AUTOSAR XML (schema 4-2-2)
package /STELLANTIS/EPT/ASWCs
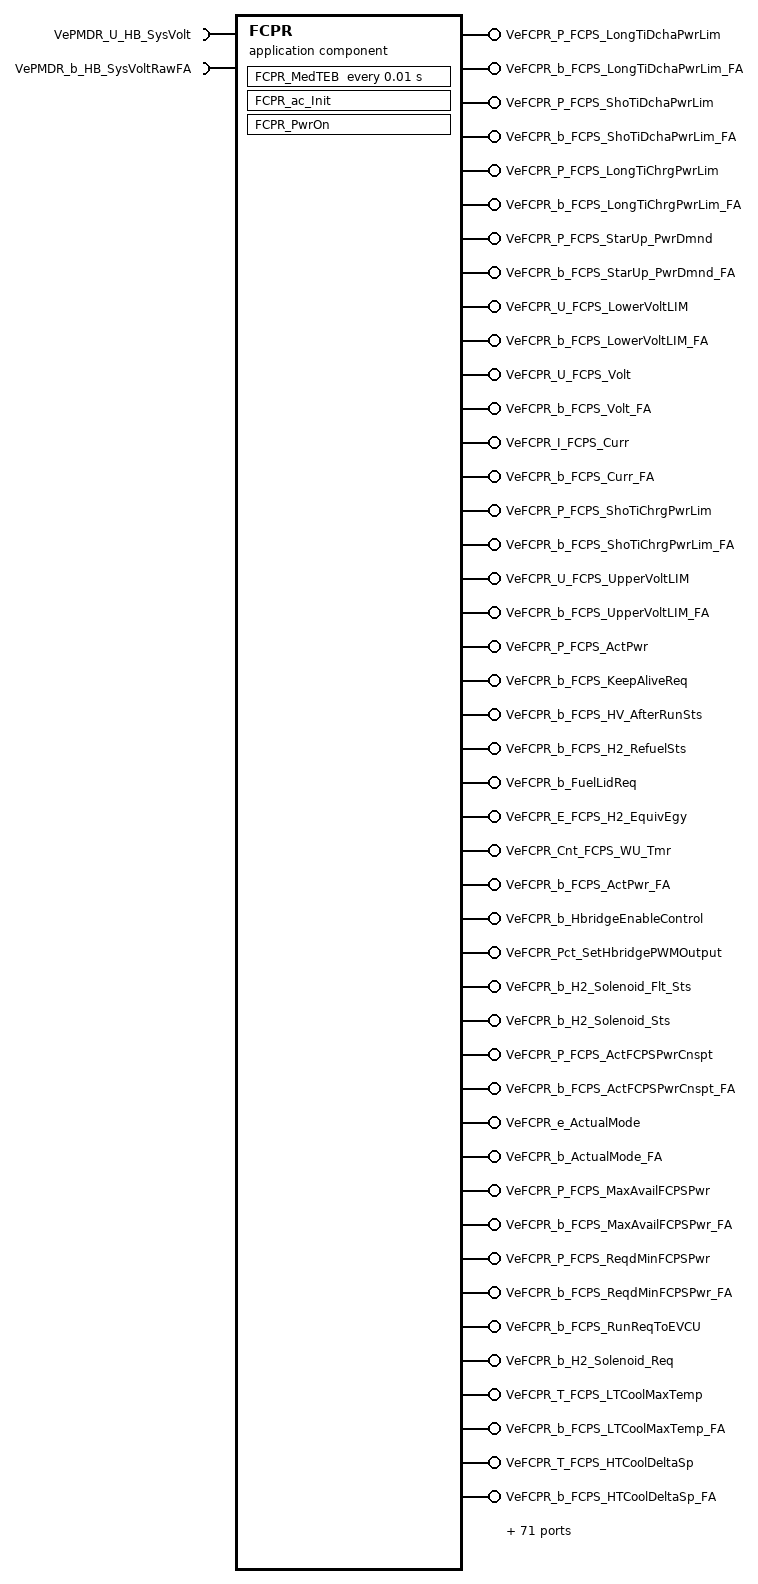
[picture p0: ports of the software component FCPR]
  application sw component type FCPR
    require port VePMDR_U_HB_SysVolt: nonqueued-receiver-com-spec{data-element=Value, init-value=0}, required-interface=VePMDR_U_HB_SysVolt
    require port VePMDR_b_HB_SysVoltRawFA: nonqueued-receiver-com-spec{data-element=Value, init-value=0}, required-interface=VePMDR_b_HB_SysVoltRawFA
    115 x provide port:
      VeFCPR_P_FCPS_LongTiDchaPwrLim: nonqueued-sender-com-spec{data-element=Value, init-value=0}, provided-interface=VeFCPR_P_FCPS_LongTiDchaPwrLim
      VeFCPR_b_FCPS_LongTiDchaPwrLim_FA: nonqueued-sender-com-spec{data-element=Value, init-value=0}, provided-interface=VeFCPR_b_FCPS_LongTiDchaPwrLim_FA
      VeFCPR_P_FCPS_ShoTiDchaPwrLim: nonqueued-sender-com-spec{data-element=Value, init-value=0}, provided-interface=VeFCPR_P_FCPS_ShoTiDchaPwrLim
      VeFCPR_b_FCPS_ShoTiDchaPwrLim_FA: nonqueued-sender-com-spec{data-element=Value, init-value=0}, provided-interface=VeFCPR_b_FCPS_ShoTiDchaPwrLim_FA
      VeFCPR_P_FCPS_LongTiChrgPwrLim: nonqueued-sender-com-spec{data-element=Value, init-value=0}, provided-interface=VeFCPR_P_FCPS_LongTiChrgPwrLim
      VeFCPR_b_FCPS_LongTiChrgPwrLim_FA: nonqueued-sender-com-spec{data-element=Value, init-value=0}, provided-interface=VeFCPR_b_FCPS_LongTiChrgPwrLim_FA
      VeFCPR_P_FCPS_StarUp_PwrDmnd: nonqueued-sender-com-spec{data-element=Value, init-value=0}, provided-interface=VeFCPR_P_FCPS_StarUp_PwrDmnd
      VeFCPR_b_FCPS_StarUp_PwrDmnd_FA: nonqueued-sender-com-spec{data-element=Value, init-value=0}, provided-interface=VeFCPR_b_FCPS_StarUp_PwrDmnd_FA
      VeFCPR_U_FCPS_LowerVoltLIM: nonqueued-sender-com-spec{data-element=Value, init-value=0}, provided-interface=VeFCPR_U_FCPS_LowerVoltLIM
      VeFCPR_b_FCPS_LowerVoltLIM_FA: nonqueued-sender-com-spec{data-element=Value, init-value=0}, provided-interface=VeFCPR_b_FCPS_LowerVoltLIM_FA
      VeFCPR_U_FCPS_Volt: nonqueued-sender-com-spec{data-element=Value, init-value=0}, provided-interface=VeFCPR_U_FCPS_Volt
      VeFCPR_b_FCPS_Volt_FA: nonqueued-sender-com-spec{data-element=Value, init-value=0}, provided-interface=VeFCPR_b_FCPS_Volt_FA
      VeFCPR_I_FCPS_Curr: nonqueued-sender-com-spec{data-element=Value, init-value=0}, provided-interface=VeFCPR_I_FCPS_Curr
      VeFCPR_b_FCPS_Curr_FA: nonqueued-sender-com-spec{data-element=Value, init-value=0}, provided-interface=VeFCPR_b_FCPS_Curr_FA
      VeFCPR_P_FCPS_ShoTiChrgPwrLim: nonqueued-sender-com-spec{data-element=Value, init-value=0}, provided-interface=VeFCPR_P_FCPS_ShoTiChrgPwrLim
      VeFCPR_b_FCPS_ShoTiChrgPwrLim_FA: nonqueued-sender-com-spec{data-element=Value, init-value=0}, provided-interface=VeFCPR_b_FCPS_ShoTiChrgPwrLim_FA
      VeFCPR_U_FCPS_UpperVoltLIM: nonqueued-sender-com-spec{data-element=Value, init-value=0}, provided-interface=VeFCPR_U_FCPS_UpperVoltLIM
      VeFCPR_b_FCPS_UpperVoltLIM_FA: nonqueued-sender-com-spec{data-element=Value, init-value=0}, provided-interface=VeFCPR_b_FCPS_UpperVoltLIM_FA
      VeFCPR_P_FCPS_ActPwr: nonqueued-sender-com-spec{data-element=Value, init-value=0}, provided-interface=VeFCPR_P_FCPS_ActPwr
      VeFCPR_b_FCPS_KeepAliveReq: nonqueued-sender-com-spec{data-element=Value, init-value=0}, provided-interface=VeFCPR_b_FCPS_KeepAliveReq
      VeFCPR_b_FCPS_HV_AfterRunSts: nonqueued-sender-com-spec{data-element=Value, init-value=0}, provided-interface=VeFCPR_b_FCPS_HV_AfterRunSts
      VeFCPR_b_FCPS_H2_RefuelSts: nonqueued-sender-com-spec{data-element=Value, init-value=0}, provided-interface=VeFCPR_b_FCPS_H2_RefuelSts
      VeFCPR_b_FuelLidReq: nonqueued-sender-com-spec{data-element=Value, init-value=0}, provided-interface=VeFCPR_b_FuelLidReq
      VeFCPR_E_FCPS_H2_EquivEgy: nonqueued-sender-com-spec{data-element=Value, init-value=0}, provided-interface=VeFCPR_E_FCPS_H2_EquivEgy
      VeFCPR_Cnt_FCPS_WU_Tmr: nonqueued-sender-com-spec{data-element=Value, init-value=0}, provided-interface=VeFCPR_Cnt_FCPS_WU_Tmr
      VeFCPR_b_FCPS_ActPwr_FA: nonqueued-sender-com-spec{data-element=Value, init-value=0}, provided-interface=VeFCPR_b_FCPS_ActPwr_FA
      VeFCPR_b_HbridgeEnableControl: nonqueued-sender-com-spec{data-element=Value, init-value=0}, provided-interface=VeFCPR_b_HbridgeEnableControl
      VeFCPR_Pct_SetHbridgePWMOutput: nonqueued-sender-com-spec{data-element=Value, init-value=0}, provided-interface=VeFCPR_Pct_SetHbridgePWMOutput
      VeFCPR_b_H2_Solenoid_Flt_Sts: nonqueued-sender-com-spec{data-element=Value, init-value=0}, provided-interface=VeFCPR_b_H2_Solenoid_Flt_Sts
      VeFCPR_b_H2_Solenoid_Sts: nonqueued-sender-com-spec{data-element=Value, init-value=0}, provided-interface=VeFCPR_b_H2_Solenoid_Sts
      VeFCPR_P_FCPS_ActFCPSPwrCnspt: nonqueued-sender-com-spec{data-element=Value, init-value=0}, provided-interface=VeFCPR_P_FCPS_ActFCPSPwrCnspt
      VeFCPR_b_FCPS_ActFCPSPwrCnspt_FA: nonqueued-sender-com-spec{data-element=Value, init-value=0}, provided-interface=VeFCPR_b_FCPS_ActFCPSPwrCnspt_FA
      VeFCPR_e_ActualMode: nonqueued-sender-com-spec{data-element=Value, init-value=CeFCPR_e_ActualMode_NotAvailable}, provided-interface=VeFCPR_e_ActualMode
      VeFCPR_b_ActualMode_FA: nonqueued-sender-com-spec{data-element=Value, init-value=0}, provided-interface=VeFCPR_b_ActualMode_FA
      VeFCPR_P_FCPS_MaxAvailFCPSPwr: nonqueued-sender-com-spec{data-element=Value, init-value=0}, provided-interface=VeFCPR_P_FCPS_MaxAvailFCPSPwr
      VeFCPR_b_FCPS_MaxAvailFCPSPwr_FA: nonqueued-sender-com-spec{data-element=Value, init-value=0}, provided-interface=VeFCPR_b_FCPS_MaxAvailFCPSPwr_FA
      VeFCPR_P_FCPS_ReqdMinFCPSPwr: nonqueued-sender-com-spec{data-element=Value, init-value=0}, provided-interface=VeFCPR_P_FCPS_ReqdMinFCPSPwr
      VeFCPR_b_FCPS_ReqdMinFCPSPwr_FA: nonqueued-sender-com-spec{data-element=Value, init-value=0}, provided-interface=VeFCPR_b_FCPS_ReqdMinFCPSPwr_FA
      VeFCPR_b_FCPS_RunReqToEVCU: nonqueued-sender-com-spec{data-element=Value, init-value=0}, provided-interface=VeFCPR_b_FCPS_RunReqToEVCU
      VeFCPR_b_H2_Solenoid_Req: nonqueued-sender-com-spec{data-element=Value, init-value=0}, provided-interface=VeFCPR_b_H2_Solenoid_Req
      VeFCPR_T_FCPS_LTCoolMaxTemp: nonqueued-sender-com-spec{data-element=Value, init-value=0}, provided-interface=VeFCPR_T_FCPS_LTCoolMaxTemp
      VeFCPR_b_FCPS_LTCoolMaxTemp_FA: nonqueued-sender-com-spec{data-element=Value, init-value=0}, provided-interface=VeFCPR_b_FCPS_LTCoolMaxTemp_FA
      VeFCPR_T_FCPS_HTCoolDeltaSp: nonqueued-sender-com-spec{data-element=Value, init-value=0}, provided-interface=VeFCPR_T_FCPS_HTCoolDeltaSp
      VeFCPR_b_FCPS_HTCoolDeltaSp_FA: nonqueued-sender-com-spec{data-element=Value, init-value=0}, provided-interface=VeFCPR_b_FCPS_HTCoolDeltaSp_FA
      VeFCPR_T_FCPS_HTCoolOutTemp: nonqueued-sender-com-spec{data-element=Value, init-value=0}, provided-interface=VeFCPR_T_FCPS_HTCoolOutTemp
      VeFCPR_b_FCPS_HTCoolOutTemp_FA: nonqueued-sender-com-spec{data-element=Value, init-value=0}, provided-interface=VeFCPR_b_FCPS_HTCoolOutTemp_FA
      VeFCPR_e_FCPS_HTCoolReq: nonqueued-sender-com-spec{data-element=Value, init-value=CeFCPR_e_No_Request}, provided-interface=VeFCPR_e_FCPS_HTCoolReq
      VeFCPR_b_FCPS_HTCoolReq_FA: nonqueued-sender-com-spec{data-element=Value, init-value=0}, provided-interface=VeFCPR_b_FCPS_HTCoolReq_FA
      VeFCPR_T_FCPS_HTCoolInTemp: nonqueued-sender-com-spec{data-element=Value, init-value=0}, provided-interface=VeFCPR_T_FCPS_HTCoolInTemp
      VeFCPR_b_FCPS_HTCoolInTemp_FA: nonqueued-sender-com-spec{data-element=Value, init-value=0}, provided-interface=VeFCPR_b_FCPS_HTCoolInTemp_FA
      VeFCPR_T_FCPS_HTCoolOutTempSp: nonqueued-sender-com-spec{data-element=Value, init-value=0}, provided-interface=VeFCPR_T_FCPS_HTCoolOutTempSp
      VeFCPR_b_FCPS_HTCoolOutTempSp_FA: nonqueued-sender-com-spec{data-element=Value, init-value=0}, provided-interface=VeFCPR_b_FCPS_HTCoolOutTempSp_FA
      VeFCPR_e_FC_DCDC_IntrlkStat: nonqueued-sender-com-spec{data-element=Value, init-value=CeHVTR_e_IntrlkNotSourced}, provided-interface=VeFCPR_e_FC_DCDC_IntrlkStat
      VeFCPR_b_FC_DCDC_IntrlkStat_FA: nonqueued-sender-com-spec{data-element=Value, init-value=0}, provided-interface=VeFCPR_b_FC_DCDC_IntrlkStat_FA
      VeFCPR_e_HEAC_IntrlkStat: nonqueued-sender-com-spec{data-element=Value, init-value=CeHVTR_e_IntrlkNotSourced}, provided-interface=VeFCPR_e_HEAC_IntrlkStat
      VeFCPR_b_HEAC_IntrlkStat_FA: nonqueued-sender-com-spec{data-element=Value, init-value=0}, provided-interface=VeFCPR_b_HEAC_IntrlkStat_FA
      VeFCPR_P_FCPS_ThermPwrCnsReq: nonqueued-sender-com-spec{data-element=Value, init-value=0}, provided-interface=VeFCPR_P_FCPS_ThermPwrCnsReq
      VeFCPR_P_FCPS_ThermPwrCnsReq_FA: nonqueued-sender-com-spec{data-element=Value, init-value=0}, provided-interface=VeFCPR_P_FCPS_ThermPwrCnsReq_FA
      FsftFCPR_I_CURRENT: server-com-spec=FsftFCPR_I_CURRENT, provided-interface=FsftFCPR_I_CURRENT
      FsftFCPR_P_FCPS_ActFCPSPwrCnspt: server-com-spec=FsftFCPR_P_FCPS_ActFCPSPwrCnspt, provided-interface=FsftFCPR_P_FCPS_ActFCPSPwrCnspt
      FsftFCPR_P_FCPS_MaxAvailFCPSPwr: server-com-spec=FsftFCPR_P_FCPS_MaxAvailFCPSPwr, provided-interface=FsftFCPR_P_FCPS_MaxAvailFCPSPwr
      FsftFCPR_P_FCPS_ReqdMinFCPSPwr: server-com-spec=FsftFCPR_P_FCPS_ReqdMinFCPSPwr, provided-interface=FsftFCPR_P_FCPS_ReqdMinFCPSPwr
      FsftFCPR_P_FCPS_THERM_PWR_CNS_REQ: server-com-spec=FsftFCPR_P_FCPS_THERM_PWR_CNS_REQ, provided-interface=FsftFCPR_P_FCPS_THERM_PWR_CNS_REQ
      FsftFCPR_P_Gen_Pwr: server-com-spec=FsftFCPR_P_Gen_Pwr, provided-interface=FsftFCPR_P_Gen_Pwr
      FsftFCPR_P_LONGTIME_CHRG_PWRLIM: server-com-spec=FsftFCPR_P_LONGTIME_CHRG_PWRLIM, provided-interface=FsftFCPR_P_LONGTIME_CHRG_PWRLIM
      FsftFCPR_P_LONGTIME_DISCHRG_PWRLIM: server-com-spec=FsftFCPR_P_LONGTIME_DISCHRG_PWRLIM, provided-interface=FsftFCPR_P_LONGTIME_DISCHRG_PWRLIM
      FsftFCPR_P_SHORTTIME_CHRG_PWRLIM: server-com-spec=FsftFCPR_P_SHORTTIME_CHRG_PWRLIM, provided-interface=FsftFCPR_P_SHORTTIME_CHRG_PWRLIM
      FsftFCPR_P_SHORTTIME_DISCHRG_PWRLIM: server-com-spec=FsftFCPR_P_SHORTTIME_DISCHRG_PWRLIM, provided-interface=FsftFCPR_P_SHORTTIME_DISCHRG_PWRLIM
      FsftFCPR_P_STARTUP_PWR_DEMAND: server-com-spec=FsftFCPR_P_STARTUP_PWR_DEMAND, provided-interface=FsftFCPR_P_STARTUP_PWR_DEMAND
      FsftFCPR_T_FCPS_HTCoolDeltaSp: server-com-spec=FsftFCPR_T_FCPS_HTCoolDeltaSp, provided-interface=FsftFCPR_T_FCPS_HTCoolDeltaSp
      FsftFCPR_T_FCPS_HTCoolInTemp: server-com-spec=FsftFCPR_T_FCPS_HTCoolInTemp, provided-interface=FsftFCPR_T_FCPS_HTCoolInTemp
      FsftFCPR_T_FCPS_HTCoolOutTemp: server-com-spec=FsftFCPR_T_FCPS_HTCoolOutTemp, provided-interface=FsftFCPR_T_FCPS_HTCoolOutTemp
      FsftFCPR_T_FCPS_HTCoolOutTempSp: server-com-spec=FsftFCPR_T_FCPS_HTCoolOutTempSp, provided-interface=FsftFCPR_T_FCPS_HTCoolOutTempSp
      FsftFCPR_T_FCPS_LTCoolMaxTemp: server-com-spec=FsftFCPR_T_FCPS_LTCoolMaxTemp, provided-interface=FsftFCPR_T_FCPS_LTCoolMaxTemp
      FsftFCPR_U_LOWER_VOLTAGE_LIM: server-com-spec=FsftFCPR_U_LOWER_VOLTAGE_LIM, provided-interface=FsftFCPR_U_LOWER_VOLTAGE_LIM
      FsftFCPR_U_UPPER_VOLTAGE_LIM: server-com-spec=FsftFCPR_U_UPPER_VOLTAGE_LIM, provided-interface=FsftFCPR_U_UPPER_VOLTAGE_LIM
      FsftFCPR_U_VOLTAGE: server-com-spec=FsftFCPR_U_VOLTAGE, provided-interface=FsftFCPR_U_VOLTAGE
      FsftFCPR_e_ActualMode: server-com-spec=FsftFCPR_e_ActualMode, provided-interface=FsftFCPR_e_ActualMode
      FsftFCPR_e_FCPS_HTCoolReq: server-com-spec=FsftFCPR_e_FCPS_HTCoolReq, provided-interface=FsftFCPR_e_FCPS_HTCoolReq
      FsftFCPR_e_FC_DCDC_IntrlkStat: server-com-spec=FsftFCPR_e_FC_DCDC_IntrlkStat, provided-interface=FsftFCPR_e_FC_DCDC_IntrlkStat
      FsftFCPR_e_HEAC_IntrlkStat: server-com-spec=FsftFCPR_e_HEAC_IntrlkStat, provided-interface=FsftFCPR_e_HEAC_IntrlkStat
      PokeFCPR_Cnt_FCPS_WU_Tmr: server-com-spec{operation=PokeFCPR_Cnt_FCPS_WU_Tmr, queue-length=1}, provided-interface=PokeFCPR_Cnt_FCPS_WU_Tmr
      PokeFCPR_E_FCPS_H2_EquivEgy: server-com-spec{operation=PokeFCPR_E_FCPS_H2_EquivEgy, queue-length=1}, provided-interface=PokeFCPR_E_FCPS_H2_EquivEgy
      PokeFCPR_I_CURRENT: server-com-spec{operation=PokeFCPR_I_CURRENT, queue-length=1}, provided-interface=PokeFCPR_I_CURRENT
      PokeFCPR_P_FCPS_ActFCPSPwrCnspt: server-com-spec{operation=PokeFCPR_P_FCPS_ActFCPSPwrCnspt, queue-length=1}, provided-interface=PokeFCPR_P_FCPS_ActFCPSPwrCnspt
      PokeFCPR_P_FCPS_MaxAvailFCPSPwr: server-com-spec{operation=PokeFCPR_P_FCPS_MaxAvailFCPSPwr, queue-length=1}, provided-interface=PokeFCPR_P_FCPS_MaxAvailFCPSPwr
      PokeFCPR_P_FCPS_ReqdMinFCPSPwr: server-com-spec{operation=PokeFCPR_P_FCPS_ReqdMinFCPSPwr, queue-length=1}, provided-interface=PokeFCPR_P_FCPS_ReqdMinFCPSPwr
      PokeFCPR_P_FCPS_THERM_PWR_CNS_REQ: server-com-spec{operation=PokeFCPR_P_FCPS_THERM_PWR_CNS_REQ, queue-length=1}, provided-interface=PokeFCPR_P_FCPS_THERM_PWR_CNS_REQ
      PokeFCPR_P_Gen_Pwr: server-com-spec{operation=PokeFCPR_P_Gen_Pwr, queue-length=1}, provided-interface=PokeFCPR_P_Gen_Pwr
      PokeFCPR_P_LONGTIME_CHRG_PWRLIM: server-com-spec{operation=PokeFCPR_P_LONGTIME_CHRG_PWRLIM, queue-length=1}, provided-interface=PokeFCPR_P_LONGTIME_CHRG_PWRLIM
      PokeFCPR_P_LONGTIME_DISCHRG_PWRLIM: server-com-spec{operation=PokeFCPR_P_LONGTIME_DISCHRG_PWRLIM, queue-length=1}, provided-interface=PokeFCPR_P_LONGTIME_DISCHRG_PWRLIM
      PokeFCPR_P_SHORTTIME_CHRG_PWRLIM: server-com-spec{operation=PokeFCPR_P_SHORTTIME_CHRG_PWRLIM, queue-length=1}, provided-interface=PokeFCPR_P_SHORTTIME_CHRG_PWRLIM
      PokeFCPR_P_SHORTTIME_DISCHRG_PWRLIM: server-com-spec{operation=PokeFCPR_P_SHORTTIME_DISCHRG_PWRLIM, queue-length=1}, provided-interface=PokeFCPR_P_SHORTTIME_DISCHRG_PWRLIM
      PokeFCPR_P_STARTUP_PWR_DEMAND: server-com-spec{operation=PokeFCPR_P_STARTUP_PWR_DEMAND, queue-length=1}, provided-interface=PokeFCPR_P_STARTUP_PWR_DEMAND
      PokeFCPR_T_FCPS_HTCoolDeltaSp: server-com-spec{operation=PokeFCPR_T_FCPS_HTCoolDeltaSp, queue-length=1}, provided-interface=PokeFCPR_T_FCPS_HTCoolDeltaSp
      PokeFCPR_T_FCPS_HTCoolInTemp: server-com-spec{operation=PokeFCPR_T_FCPS_HTCoolInTemp, queue-length=1}, provided-interface=PokeFCPR_T_FCPS_HTCoolInTemp
      PokeFCPR_T_FCPS_HTCoolOutTemp: server-com-spec{operation=PokeFCPR_T_FCPS_HTCoolOutTemp, queue-length=1}, provided-interface=PokeFCPR_T_FCPS_HTCoolOutTemp
      PokeFCPR_T_FCPS_HTCoolOutTempSp: server-com-spec{operation=PokeFCPR_T_FCPS_HTCoolOutTempSp, queue-length=1}, provided-interface=PokeFCPR_T_FCPS_HTCoolOutTempSp
      PokeFCPR_T_FCPS_LTCoolMaxTemp: server-com-spec{operation=PokeFCPR_T_FCPS_LTCoolMaxTemp, queue-length=1}, provided-interface=PokeFCPR_T_FCPS_LTCoolMaxTemp
      PokeFCPR_U_CoverMtrPosn: server-com-spec{operation=PokeFCPR_U_CoverMtrPosn, queue-length=1}, provided-interface=PokeFCPR_U_CoverMtrPosn
      PokeFCPR_U_HB_SysVolt: server-com-spec{operation=PokeFCPR_U_HB_SysVolt, queue-length=1}, provided-interface=PokeFCPR_U_HB_SysVolt
      PokeFCPR_U_LOWER_VOLTAGE_LIM: server-com-spec{operation=PokeFCPR_U_LOWER_VOLTAGE_LIM, queue-length=1}, provided-interface=PokeFCPR_U_LOWER_VOLTAGE_LIM
      PokeFCPR_U_UPPER_VOLTAGE_LIM: server-com-spec{operation=PokeFCPR_U_UPPER_VOLTAGE_LIM, queue-length=1}, provided-interface=PokeFCPR_U_UPPER_VOLTAGE_LIM
      PokeFCPR_U_VOLTAGE: server-com-spec{operation=PokeFCPR_U_VOLTAGE, queue-length=1}, provided-interface=PokeFCPR_U_VOLTAGE
      PokeFCPR_b_FCPS_RunReqToEVCU: server-com-spec{operation=PokeFCPR_b_FCPS_RunReqToEVCU, queue-length=1}, provided-interface=PokeFCPR_b_FCPS_RunReqToEVCU
      PokeFCPR_b_FuelLidReq: server-com-spec{operation=PokeFCPR_b_FuelLidReq, queue-length=1}, provided-interface=PokeFCPR_b_FuelLidReq
      PokeFCPR_b_H2_Refuel_Sts: server-com-spec{operation=PokeFCPR_b_H2_Refuel_Sts, queue-length=1}, provided-interface=PokeFCPR_b_H2_Refuel_Sts
      PokeFCPR_b_H2_Solenoid_Req: server-com-spec{operation=PokeFCPR_b_H2_Solenoid_Req, queue-length=1}, provided-interface=PokeFCPR_b_H2_Solenoid_Req
      PokeFCPR_b_HV_AfterRun_Sts: server-com-spec{operation=PokeFCPR_b_HV_AfterRun_Sts, queue-length=1}, provided-interface=PokeFCPR_b_HV_AfterRun_Sts
      PokeFCPR_b_KeepAlive_Req: server-com-spec{operation=PokeFCPR_b_KeepAlive_Req, queue-length=1}, provided-interface=PokeFCPR_b_KeepAlive_Req
      PokeFCPR_e_ActualMode: server-com-spec{operation=PokeFCPR_e_ActualMode, queue-length=1}, provided-interface=PokeFCPR_e_ActualMode
      PokeFCPR_e_FCPS_HTCoolReq: server-com-spec{operation=PokeFCPR_e_FCPS_HTCoolReq, queue-length=1}, provided-interface=PokeFCPR_e_FCPS_HTCoolReq
      PokeFCPR_e_FC_DCDC_IntrlkStat: server-com-spec{operation=PokeFCPR_e_FC_DCDC_IntrlkStat, queue-length=1}, provided-interface=PokeFCPR_e_FC_DCDC_IntrlkStat
      PokeFCPR_e_HEAC_IntrlkStat: server-com-spec{operation=PokeFCPR_e_HEAC_IntrlkStat, queue-length=1}, provided-interface=PokeFCPR_e_HEAC_IntrlkStat
      PokeFCPR_e_UpdateHBridgeDiagData: server-com-spec{operation=PokeFCPR_e_UpdateHBridgeDiagData, queue-length=1}, provided-interface=PokeFCPR_e_UpdateHBridgeDiagData
    behavior IB_FCPR: data-type-mapping=msADTtoIDTMapping, handle-termination-and-restart=NO-SUPPORT
      timing event Event_MedTEB: start-on-event=FCPR_MedTEB, period=0.01
      init event Event_FCPR_ac_Init: start-on-event=FCPR_ac_Init
      init event Event_PwrOn: start-on-event=FCPR_PwrOn
      runnable FCPR_ac_Init
        data-send-points:
          4 x access:
            OUT_VeFCPR_e_ActualMode_Value: accessed-variable=VeFCPR_e_ActualMode.Value
            OUT_VeFCPR_e_FCPS_HTCoolReq_Value: accessed-variable=VeFCPR_e_FCPS_HTCoolReq.Value
            OUT_VeFCPR_e_FC_DCDC_IntrlkStat_Value: accessed-variable=VeFCPR_e_FC_DCDC_IntrlkStat.Value
            OUT_VeFCPR_e_HEAC_IntrlkStat_Value: accessed-variable=VeFCPR_e_HEAC_IntrlkStat.Value
      runnable FCPR_PwrOn
        data-send-points:
          58 x access:
            OUT_VeFCPR_P_FCPS_LongTiDchaPwrLim_Value: accessed-variable=VeFCPR_P_FCPS_LongTiDchaPwrLim.Value
            OUT_VeFCPR_P_FCPS_ShoTiDchaPwrLim_Value: accessed-variable=VeFCPR_P_FCPS_ShoTiDchaPwrLim.Value
            OUT_VeFCPR_b_FCPS_KeepAliveReq_Value: accessed-variable=VeFCPR_b_FCPS_KeepAliveReq.Value
            OUT_VeFCPR_b_FCPS_HV_AfterRunSts_Value: accessed-variable=VeFCPR_b_FCPS_HV_AfterRunSts.Value
            OUT_VeFCPR_b_FCPS_H2_RefuelSts_Value: accessed-variable=VeFCPR_b_FCPS_H2_RefuelSts.Value
            OUT_VeFCPR_b_FuelLidReq_Value: accessed-variable=VeFCPR_b_FuelLidReq.Value
            OUT_VeFCPR_b_FCPS_ShoTiDchaPwrLim_FA_Value: accessed-variable=VeFCPR_b_FCPS_ShoTiDchaPwrLim_FA.Value
            OUT_VeFCPR_b_FCPS_LongTiChrgPwrLim_FA_Value: accessed-variable=VeFCPR_b_FCPS_LongTiChrgPwrLim_FA.Value
            OUT_VeFCPR_E_FCPS_H2_EquivEgy_Value: accessed-variable=VeFCPR_E_FCPS_H2_EquivEgy.Value
            OUT_VeFCPR_b_FCPS_StarUp_PwrDmnd_FA_Value: accessed-variable=VeFCPR_b_FCPS_StarUp_PwrDmnd_FA.Value
            OUT_VeFCPR_Cnt_FCPS_WU_Tmr_Value: accessed-variable=VeFCPR_Cnt_FCPS_WU_Tmr.Value
            OUT_VeFCPR_P_FCPS_LongTiChrgPwrLim_Value: accessed-variable=VeFCPR_P_FCPS_LongTiChrgPwrLim.Value
            OUT_VeFCPR_b_FCPS_LowerVoltLIM_FA_Value: accessed-variable=VeFCPR_b_FCPS_LowerVoltLIM_FA.Value
            OUT_VeFCPR_b_FCPS_Volt_FA_Value: accessed-variable=VeFCPR_b_FCPS_Volt_FA.Value
            OUT_VeFCPR_b_FCPS_Curr_FA_Value: accessed-variable=VeFCPR_b_FCPS_Curr_FA.Value
            OUT_VeFCPR_b_FCPS_ShoTiChrgPwrLim_FA_Value: accessed-variable=VeFCPR_b_FCPS_ShoTiChrgPwrLim_FA.Value
            OUT_VeFCPR_b_FCPS_UpperVoltLIM_FA_Value: accessed-variable=VeFCPR_b_FCPS_UpperVoltLIM_FA.Value
            OUT_VeFCPR_b_FCPS_ActPwr_FA_Value: accessed-variable=VeFCPR_b_FCPS_ActPwr_FA.Value
            OUT_VeFCPR_P_FCPS_ShoTiChrgPwrLim_Value: accessed-variable=VeFCPR_P_FCPS_ShoTiChrgPwrLim.Value
            OUT_VeFCPR_b_FCPS_LongTiDchaPwrLim_FA_Value: accessed-variable=VeFCPR_b_FCPS_LongTiDchaPwrLim_FA.Value
            OUT_VeFCPR_P_FCPS_StarUp_PwrDmnd_Value: accessed-variable=VeFCPR_P_FCPS_StarUp_PwrDmnd.Value
            OUT_VeFCPR_U_FCPS_LowerVoltLIM_Value: accessed-variable=VeFCPR_U_FCPS_LowerVoltLIM.Value
            OUT_VeFCPR_U_FCPS_UpperVoltLIM_Value: accessed-variable=VeFCPR_U_FCPS_UpperVoltLIM.Value
            OUT_VeFCPR_U_FCPS_Volt_Value: accessed-variable=VeFCPR_U_FCPS_Volt.Value
            OUT_VeFCPR_I_FCPS_Curr_Value: accessed-variable=VeFCPR_I_FCPS_Curr.Value
            OUT_VeFCPR_P_FCPS_ActPwr_Value: accessed-variable=VeFCPR_P_FCPS_ActPwr.Value
            OUT_VeFCPR_b_H2_Solenoid_Flt_Sts_Value: accessed-variable=VeFCPR_b_H2_Solenoid_Flt_Sts.Value
            OUT_VeFCPR_b_H2_Solenoid_Sts_Value: accessed-variable=VeFCPR_b_H2_Solenoid_Sts.Value
            OUT_VeFCPR_b_HbridgeEnableControl_Value: accessed-variable=VeFCPR_b_HbridgeEnableControl.Value
            OUT_VeFCPR_Pct_SetHbridgePWMOutput_Value: accessed-variable=VeFCPR_Pct_SetHbridgePWMOutput.Value
            OUT_VeFCPR_P_FCPS_ActFCPSPwrCnspt_Value: accessed-variable=VeFCPR_P_FCPS_ActFCPSPwrCnspt.Value
            OUT_VeFCPR_b_FCPS_ActFCPSPwrCnspt_FA_Value: accessed-variable=VeFCPR_b_FCPS_ActFCPSPwrCnspt_FA.Value
            OUT_VeFCPR_e_ActualMode_Value: accessed-variable=VeFCPR_e_ActualMode.Value
            OUT_VeFCPR_b_ActualMode_FA_Value: accessed-variable=VeFCPR_b_ActualMode_FA.Value
            OUT_VeFCPR_P_FCPS_MaxAvailFCPSPwr_Value: accessed-variable=VeFCPR_P_FCPS_MaxAvailFCPSPwr.Value
            OUT_VeFCPR_b_FCPS_MaxAvailFCPSPwr_FA_Value: accessed-variable=VeFCPR_b_FCPS_MaxAvailFCPSPwr_FA.Value
            OUT_VeFCPR_P_FCPS_ReqdMinFCPSPwr_Value: accessed-variable=VeFCPR_P_FCPS_ReqdMinFCPSPwr.Value
            OUT_VeFCPR_b_FCPS_ReqdMinFCPSPwr_FA_Value: accessed-variable=VeFCPR_b_FCPS_ReqdMinFCPSPwr_FA.Value
            OUT_VeFCPR_b_FCPS_RunReqToEVCU_Value: accessed-variable=VeFCPR_b_FCPS_RunReqToEVCU.Value
            OUT_VeFCPR_T_FCPS_LTCoolMaxTemp_Value: accessed-variable=VeFCPR_T_FCPS_LTCoolMaxTemp.Value
            OUT_VeFCPR_T_FCPS_HTCoolDeltaSp_Value: accessed-variable=VeFCPR_T_FCPS_HTCoolDeltaSp.Value
            OUT_VeFCPR_T_FCPS_HTCoolOutTemp_Value: accessed-variable=VeFCPR_T_FCPS_HTCoolOutTemp.Value
            OUT_VeFCPR_e_FCPS_HTCoolReq_Value: accessed-variable=VeFCPR_e_FCPS_HTCoolReq.Value
            OUT_VeFCPR_T_FCPS_HTCoolInTemp_Value: accessed-variable=VeFCPR_T_FCPS_HTCoolInTemp.Value
            OUT_VeFCPR_T_FCPS_HTCoolOutTempSp_Value: accessed-variable=VeFCPR_T_FCPS_HTCoolOutTempSp.Value
            OUT_VeFCPR_e_FC_DCDC_IntrlkStat_Value: accessed-variable=VeFCPR_e_FC_DCDC_IntrlkStat.Value
            OUT_VeFCPR_b_FCPS_LTCoolMaxTemp_FA_Value: accessed-variable=VeFCPR_b_FCPS_LTCoolMaxTemp_FA.Value
            OUT_VeFCPR_b_FCPS_HTCoolDeltaSp_FA_Value: accessed-variable=VeFCPR_b_FCPS_HTCoolDeltaSp_FA.Value
            OUT_VeFCPR_b_FCPS_HTCoolOutTemp_FA_Value: accessed-variable=VeFCPR_b_FCPS_HTCoolOutTemp_FA.Value
            OUT_VeFCPR_b_FCPS_HTCoolReq_FA_Value: accessed-variable=VeFCPR_b_FCPS_HTCoolReq_FA.Value
            OUT_VeFCPR_b_FCPS_HTCoolInTemp_FA_Value: accessed-variable=VeFCPR_b_FCPS_HTCoolInTemp_FA.Value
            OUT_VeFCPR_b_FCPS_HTCoolOutTempSp_FA_Value: accessed-variable=VeFCPR_b_FCPS_HTCoolOutTempSp_FA.Value
            OUT_VeFCPR_b_FC_DCDC_IntrlkStat_FA_Value: accessed-variable=VeFCPR_b_FC_DCDC_IntrlkStat_FA.Value
            OUT_VeFCPR_b_HEAC_IntrlkStat_FA_Value: accessed-variable=VeFCPR_b_HEAC_IntrlkStat_FA.Value
            OUT_VeFCPR_b_H2_Solenoid_Req_Value: accessed-variable=VeFCPR_b_H2_Solenoid_Req.Value
            OUT_VeFCPR_e_HEAC_IntrlkStat_Value: accessed-variable=VeFCPR_e_HEAC_IntrlkStat.Value
            OUT_VeFCPR_P_FCPS_ThermPwrCnsReq_Value: accessed-variable=VeFCPR_P_FCPS_ThermPwrCnsReq.Value
            OUT_VeFCPR_P_FCPS_ThermPwrCnsReq_FA_Value: accessed-variable=VeFCPR_P_FCPS_ThermPwrCnsReq_FA.Value
      runnable FCPR_MedTEB
        data-receive-point-by-arguments:
          access IN_VePMDR_U_HB_SysVolt_Value: accessed-variable=VePMDR_U_HB_SysVolt.Value
          access IN_VePMDR_b_HB_SysVoltRawFA_Value: accessed-variable=VePMDR_b_HB_SysVoltRawFA.Value
        data-send-points:
          6 x access:
            OUT_VeFCPR_b_H2_Solenoid_Flt_Sts_Value: accessed-variable=VeFCPR_b_H2_Solenoid_Flt_Sts.Value
            OUT_VeFCPR_b_H2_Solenoid_Sts_Value: accessed-variable=VeFCPR_b_H2_Solenoid_Sts.Value
            OUT_VeFCPR_b_HbridgeEnableControl_Value: accessed-variable=VeFCPR_b_HbridgeEnableControl.Value
            OUT_VeFCPR_Pct_SetHbridgePWMOutput_Value: accessed-variable=VeFCPR_Pct_SetHbridgePWMOutput.Value
            OUT_VeFCPR_b_FCPS_HV_AfterRunSts_Value: accessed-variable=VeFCPR_b_FCPS_HV_AfterRunSts.Value
            OUT_VeFCPR_b_FCPS_H2_RefuelSts_Value: accessed-variable=VeFCPR_b_FCPS_H2_RefuelSts.Value
      variation point proxy Variant_FCPR_1: category=CONDITION, condition-access=0
